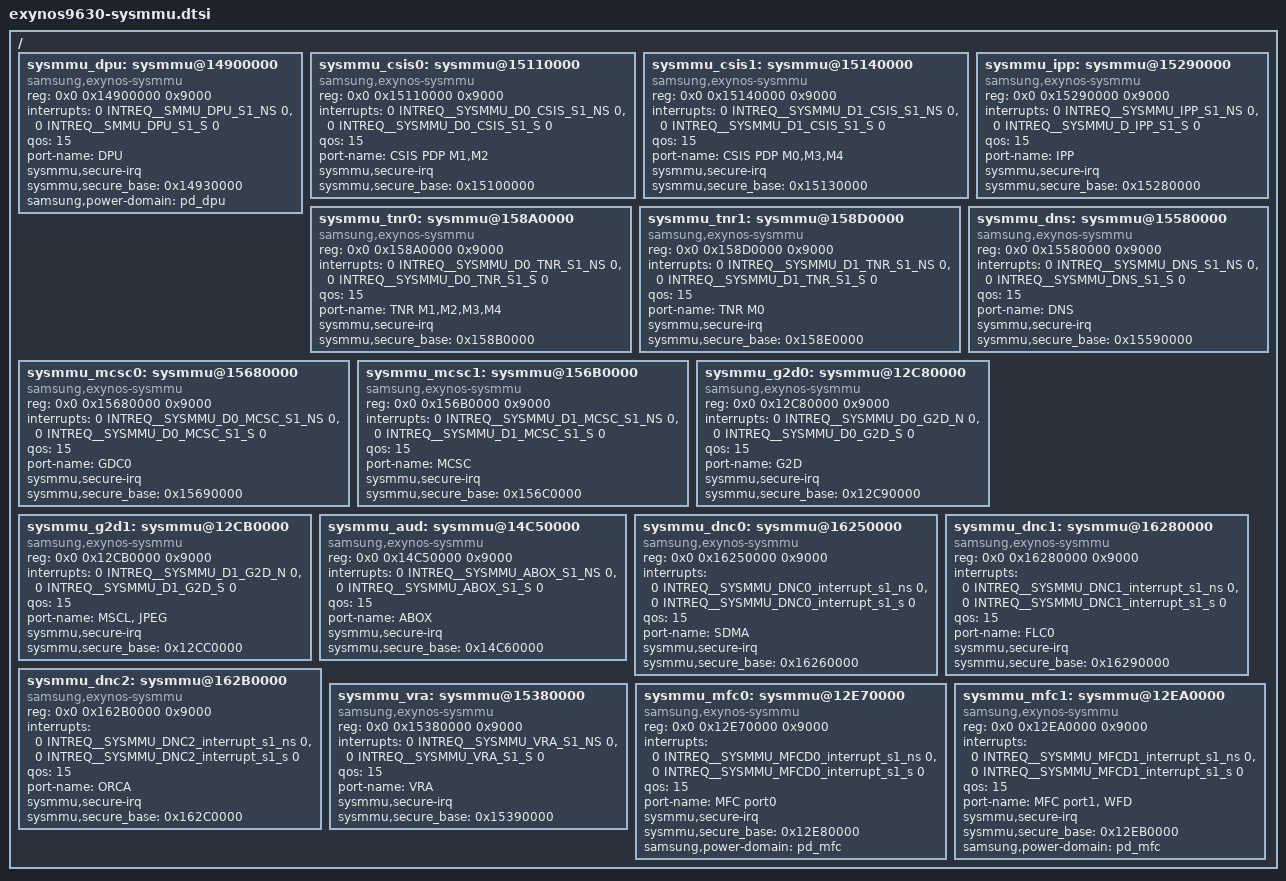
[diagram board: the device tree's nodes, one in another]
/*
 * SAMSUNG EXYNOS9610 SoC device tree source
 *
 * Copyright (c) 2018 Samsung Electronics Co., Ltd.
 *		http://www.samsung.com
 *
 * SAMSUNG EXYNOS9610 SoC device nodes are listed in this file.
 * EXYNOS9610 based board files can include this file and provide
 * values for board specfic bindings.
 *
 * This program is free software; you can redistribute it and/or modify
 * it under the terms of the GNU General Public License version 2 as
 * published by the Free Software Foundation.
 */

#include <dt-bindings/interrupt-controller/arm-gic.h>
#include <dt-bindings/interrupt-controller/exynos9630.h>
#include <dt-bindings/sysmmu/sysmmu.h>

/ {
	sysmmu_dpu: sysmmu@14900000 {
		compatible = "samsung,exynos-sysmmu";
		reg = <0x0 0x14900000 0x9000>;
		interrupts = <0 INTREQ__SMMU_DPU_S1_NS 0>,
			     <0 INTREQ__SMMU_DPU_S1_S 0>;
		qos = <15>;
		port-name = "DPU";
		sysmmu,secure-irq;
		sysmmu,secure_base = <0x14930000>;
		#iommu-cells = <0>;
		samsung,power-domain = <&pd_dpu>;
	};

	sysmmu_csis0: sysmmu@15110000 {
		compatible = "samsung,exynos-sysmmu";
		reg = <0x0 0x15110000 0x9000>;
		interrupts = <0 INTREQ__SYSMMU_D0_CSIS_S1_NS 0>,
			     <0 INTREQ__SYSMMU_D0_CSIS_S1_S 0>;
		qos = <15>;
		port-name = "CSIS PDP M1,M2";
		sysmmu,secure-irq;
		sysmmu,secure_base = <0x15100000>;
		#iommu-cells = <0>;
	};

	sysmmu_csis1: sysmmu@15140000 {
		compatible = "samsung,exynos-sysmmu";
		reg = <0x0 0x15140000 0x9000>;
		interrupts = <0 INTREQ__SYSMMU_D1_CSIS_S1_NS 0>,
			     <0 INTREQ__SYSMMU_D1_CSIS_S1_S 0>;
		qos = <15>;
		port-name = "CSIS PDP M0,M3,M4";
		sysmmu,secure-irq;
		sysmmu,secure_base = <0x15130000>;
		#iommu-cells = <0>;
	};

	sysmmu_ipp: sysmmu@15290000 {
		compatible = "samsung,exynos-sysmmu";
		reg = <0x0 0x15290000 0x9000>;
		interrupts = <0 INTREQ__SYSMMU_IPP_S1_NS 0>,
			     <0 INTREQ__SYSMMU_D_IPP_S1_S 0>;
		qos = <15>;
		port-name = "IPP";
		sysmmu,secure-irq;
		sysmmu,secure_base = <0x15280000>;
		#iommu-cells = <0>;
	};

	sysmmu_tnr0: sysmmu@158A0000 {
		compatible = "samsung,exynos-sysmmu";
		reg = <0x0 0x158A0000 0x9000>;
		interrupts = <0 INTREQ__SYSMMU_D0_TNR_S1_NS 0>,
			     <0 INTREQ__SYSMMU_D0_TNR_S1_S 0>;
		qos = <15>;
		port-name = "TNR M1,M2,M3,M4";
		sysmmu,secure-irq;
		sysmmu,secure_base = <0x158B0000>;
		#iommu-cells = <0>;
	};

	sysmmu_tnr1: sysmmu@158D0000 {
		compatible = "samsung,exynos-sysmmu";
		reg = <0x0 0x158D0000 0x9000>;
		interrupts = <0 INTREQ__SYSMMU_D1_TNR_S1_NS 0>,
			     <0 INTREQ__SYSMMU_D1_TNR_S1_S 0>;
		qos = <15>;
		port-name = "TNR M0";
		sysmmu,secure-irq;
		sysmmu,secure_base = <0x158E0000>;
		#iommu-cells = <0>;
	};

	sysmmu_dns: sysmmu@15580000 {
		compatible = "samsung,exynos-sysmmu";
		reg = <0x0 0x15580000 0x9000>;
		interrupts = <0 INTREQ__SYSMMU_DNS_S1_NS 0>,
			     <0 INTREQ__SYSMMU_DNS_S1_S 0>;
		qos = <15>;
		port-name = "DNS";
		sysmmu,secure-irq;
		sysmmu,secure_base = <0x15590000>;
		#iommu-cells = <0>;
	};

	sysmmu_mcsc0: sysmmu@15680000 {
		compatible = "samsung,exynos-sysmmu";
		reg = <0x0 0x15680000 0x9000>;
		interrupts = <0 INTREQ__SYSMMU_D0_MCSC_S1_NS 0>,
			     <0 INTREQ__SYSMMU_D0_MCSC_S1_S 0>;
		qos = <15>;
		port-name = "GDC0";
		sysmmu,secure-irq;
		sysmmu,secure_base = <0x15690000>;
		#iommu-cells = <0>;
	};

	sysmmu_mcsc1: sysmmu@156B0000 {
		compatible = "samsung,exynos-sysmmu";
		reg = <0x0 0x156B0000 0x9000>;
		interrupts = <0 INTREQ__SYSMMU_D1_MCSC_S1_NS 0>,
			     <0 INTREQ__SYSMMU_D1_MCSC_S1_S 0>;
		qos = <15>;
		port-name = "MCSC";
		sysmmu,secure-irq;
		sysmmu,secure_base = <0x156C0000>;
		#iommu-cells = <0>;
	};

	sysmmu_g2d0: sysmmu@12C80000 {
		compatible = "samsung,exynos-sysmmu";
		reg = <0x0 0x12C80000 0x9000>;
		interrupts = <0 INTREQ__SYSMMU_D0_G2D_N 0>,
			     <0 INTREQ__SYSMMU_D0_G2D_S 0>;
		qos = <15>;
		port-name = "G2D";
		sysmmu,secure-irq;
		sysmmu,secure_base = <0x12C90000>;
		#iommu-cells = <0>;
	};

	sysmmu_g2d1: sysmmu@12CB0000 {
		compatible = "samsung,exynos-sysmmu";
		reg = <0x0 0x12CB0000 0x9000>;
		interrupts = <0 INTREQ__SYSMMU_D1_G2D_N 0>,
			     <0 INTREQ__SYSMMU_D1_G2D_S 0>;
		qos = <15>;
		port-name = "MSCL, JPEG";
		sysmmu,secure-irq;
		sysmmu,secure_base = <0x12CC0000>;
		#iommu-cells = <0>;
	};

	sysmmu_aud: sysmmu@14C50000 {
		compatible = "samsung,exynos-sysmmu";
		reg = <0x0 0x14C50000 0x9000>;
		interrupts = <0 INTREQ__SYSMMU_ABOX_S1_NS 0>,
			     <0 INTREQ__SYSMMU_ABOX_S1_S 0>;
		qos = <15>;
		port-name = "ABOX";
		sysmmu,secure-irq;
		sysmmu,secure_base = <0x14C60000>;
		#iommu-cells = <0>;
	};

	sysmmu_dnc0: sysmmu@16250000 {
		compatible = "samsung,exynos-sysmmu";
		reg = <0x0 0x16250000 0x9000>;
		interrupts = <0 INTREQ__SYSMMU_DNC0_interrupt_s1_ns 0>,
			     <0 INTREQ__SYSMMU_DNC0_interrupt_s1_s 0>;
		qos = <15>;
		port-name = "SDMA";
		sysmmu,secure-irq;
		sysmmu,secure_base = <0x16260000>;
		#iommu-cells = <0>;
	};

	sysmmu_dnc1: sysmmu@16280000 {
		compatible = "samsung,exynos-sysmmu";
		reg = <0x0 0x16280000 0x9000>;
		interrupts = <0 INTREQ__SYSMMU_DNC1_interrupt_s1_ns 0>,
			     <0 INTREQ__SYSMMU_DNC1_interrupt_s1_s 0>;
		qos = <15>;
		port-name = "FLC0";
		sysmmu,secure-irq;
		sysmmu,secure_base = <0x16290000>;
		#iommu-cells = <0>;
	};

	sysmmu_dnc2: sysmmu@162B0000 {
		compatible = "samsung,exynos-sysmmu";
		reg = <0x0 0x162B0000 0x9000>;
		interrupts = <0 INTREQ__SYSMMU_DNC2_interrupt_s1_ns 0>,
			     <0 INTREQ__SYSMMU_DNC2_interrupt_s1_s 0>;
		qos = <15>;
		port-name = "ORCA";
		sysmmu,secure-irq;
		sysmmu,secure_base = <0x162C0000>;
		#iommu-cells = <0>;
	};

	sysmmu_vra: sysmmu@15380000 {
		compatible = "samsung,exynos-sysmmu";
		reg = <0x0 0x15380000 0x9000>;
		interrupts = <0 INTREQ__SYSMMU_VRA_S1_NS 0>,
			     <0 INTREQ__SYSMMU_VRA_S1_S 0>;
		qos = <15>;
		port-name = "VRA";
		sysmmu,secure-irq;
		sysmmu,secure_base = <0x15390000>;
		#iommu-cells = <0>;
	};

	sysmmu_mfc0: sysmmu@12E70000 {
		compatible = "samsung,exynos-sysmmu";
		reg = <0x0 0x12E70000 0x9000>;
		interrupts = <0 INTREQ__SYSMMU_MFCD0_interrupt_s1_ns 0>,
			     <0 INTREQ__SYSMMU_MFCD0_interrupt_s1_s 0>;
		qos = <15>;
		port-name = "MFC port0";
		sysmmu,secure-irq;
		sysmmu,secure_base = <0x12E80000>;
		#iommu-cells = <0>;
		samsung,power-domain = <&pd_mfc>;
	};

	sysmmu_mfc1: sysmmu@12EA0000 {
		compatible = "samsung,exynos-sysmmu";
		reg = <0x0 0x12EA0000 0x9000>;
		interrupts = <0 INTREQ__SYSMMU_MFCD1_interrupt_s1_ns 0>,
			     <0 INTREQ__SYSMMU_MFCD1_interrupt_s1_s 0>;
		qos = <15>;
		port-name = "MFC port1, WFD";
		sysmmu,secure-irq;
		sysmmu,secure_base = <0x12EB0000>;
		#iommu-cells = <0>;
		samsung,power-domain = <&pd_mfc>;
	};
};
